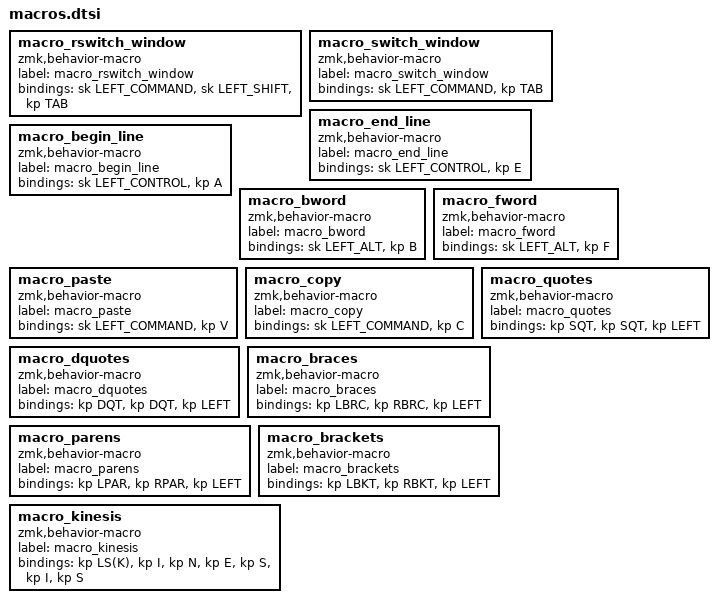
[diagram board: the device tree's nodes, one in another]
macro_rswitch_window: macro_rswitch_window{
compatible = "zmk,behavior-macro";
label = "macro_rswitch_window";
#binding-cells = <0>;
bindings = <&sk LEFT_COMMAND>, <&sk LEFT_SHIFT>, <&kp TAB>;
};
macro_switch_window: macro_switch_window{
compatible = "zmk,behavior-macro";
label = "macro_switch_window";
#binding-cells = <0>;
bindings = <&sk LEFT_COMMAND>, <&kp TAB>;
};
macro_end_line: macro_end_line{
compatible = "zmk,behavior-macro";
label = "macro_end_line";
#binding-cells = <0>;
bindings = <&sk LEFT_CONTROL>, <&kp E>;
};
macro_begin_line: macro_begin_line{
compatible = "zmk,behavior-macro";
label = "macro_begin_line";
#binding-cells = <0>;
bindings = <&sk LEFT_CONTROL>, <&kp A>;
};
macro_bword: macro_bword{
compatible = "zmk,behavior-macro";
label = "macro_bword";
#binding-cells = <0>;
bindings = <&sk LEFT_ALT>, <&kp B>;
};
macro_fword: macro_fword{
compatible = "zmk,behavior-macro";
label = "macro_fword";
#binding-cells = <0>;
bindings = <&sk LEFT_ALT>, <&kp F>;
};
macro_paste: macro_paste{
compatible = "zmk,behavior-macro";
label = "macro_paste";
#binding-cells = <0>;
bindings = <&sk LEFT_COMMAND>, <&kp V>;
};
macro_copy: macro_copy{
compatible = "zmk,behavior-macro";
label = "macro_copy";
#binding-cells = <0>;
bindings = <&sk LEFT_COMMAND>, <&kp C>;
};
macro_quotes: macro_quotes{
compatible = "zmk,behavior-macro";
label = "macro_quotes";
#binding-cells = <0>;
bindings = <&kp SQT>, <&kp SQT>, <&kp LEFT>;
};
macro_dquotes: macro_dquotes{
compatible = "zmk,behavior-macro";
label = "macro_dquotes";
#binding-cells = <0>;
bindings = <&kp DQT>, <&kp DQT>, <&kp LEFT>;
};
macro_braces: macro_braces{
compatible = "zmk,behavior-macro";
label = "macro_braces";
#binding-cells = <0>;
bindings = <&kp LBRC>, <&kp RBRC>, <&kp LEFT>;
};
macro_parens: macro_parens{
compatible = "zmk,behavior-macro";
label = "macro_parens";
#binding-cells = <0>;
bindings = <&kp LPAR>, <&kp RPAR>, <&kp LEFT>;
};
macro_brackets: macro_brackets{
compatible = "zmk,behavior-macro";
label = "macro_brackets";
#binding-cells = <0>;
bindings = <&kp LBKT>, <&kp RBKT>, <&kp LEFT>;
};
macro_kinesis: macro_kinesis{
compatible = "zmk,behavior-macro";
label = "macro_kinesis";
#binding-cells = <0>;
bindings = <&kp LS(K)>, <&kp I>, <&kp N>, <&kp E>, <&kp S>, <&kp I>, <&kp S>;
};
